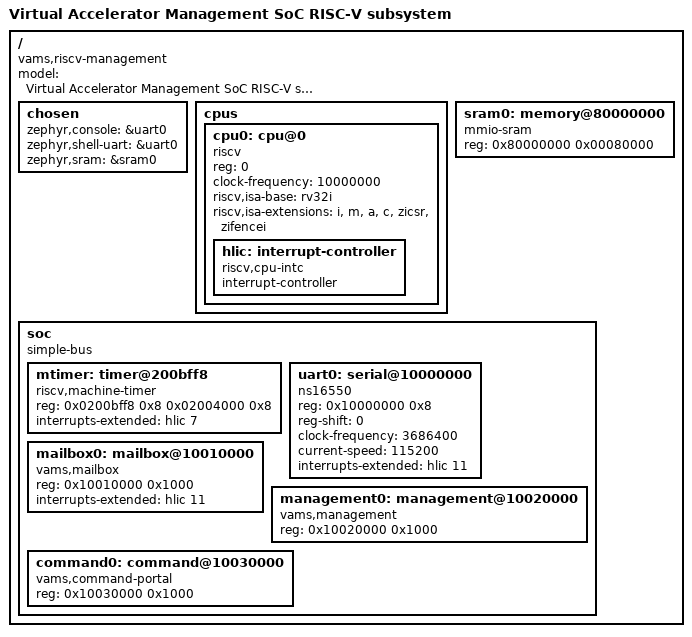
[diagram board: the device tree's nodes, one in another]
/* SPDX-License-Identifier: MIT */

/dts-v1/;

/ {
	model = "Virtual Accelerator Management SoC RISC-V subsystem";
	compatible = "vams,riscv-management";
	#address-cells = <1>;
	#size-cells = <1>;

	chosen {
		zephyr,console = &uart0;
		zephyr,shell-uart = &uart0;
		zephyr,sram = &sram0;
	};

	cpus {
		#address-cells = <1>;
		#size-cells = <0>;

		cpu0: cpu@0 {
			compatible = "riscv";
			device_type = "cpu";
			reg = <0>;
			clock-frequency = <10000000>;
			riscv,isa-base = "rv32i";
			riscv,isa-extensions = "i", "m", "a", "c", "zicsr", "zifencei";
			status = "okay";

			hlic: interrupt-controller {
				compatible = "riscv,cpu-intc";
				#address-cells = <0>;
				#interrupt-cells = <1>;
				interrupt-controller;
			};
		};
	};

	sram0: memory@80000000 {
		compatible = "mmio-sram";
		device_type = "memory";
		reg = <0x80000000 0x00080000>;
	};

	soc {
		compatible = "simple-bus";
		#address-cells = <1>;
		#size-cells = <1>;
		ranges;

		mtimer: timer@200bff8 {
			compatible = "riscv,machine-timer";
			reg = <0x0200bff8 0x8 0x02004000 0x8>;
			reg-names = "mtime", "mtimecmp";
			interrupts-extended = <&hlic 7>;
			status = "okay";
		};

		uart0: serial@10000000 {
			compatible = "ns16550";
			reg = <0x10000000 0x8>;
			reg-shift = <0>;
			clock-frequency = <3686400>;
			current-speed = <115200>;
			interrupts-extended = <&hlic 11>;
			status = "okay";
		};

		mailbox0: mailbox@10010000 {
			compatible = "vams,mailbox";
			reg = <0x10010000 0x1000>;
			interrupts-extended = <&hlic 11>;
			status = "okay";
		};

		management0: management@10020000 {
			compatible = "vams,management";
			reg = <0x10020000 0x1000>;
			status = "okay";
		};

		command0: command@10030000 {
			compatible = "vams,command-portal";
			reg = <0x10030000 0x1000>;
			status = "okay";
		};
	};
};
